VERSION "1.3 corrected-charging-mode-source"

NS_ :

BS_:

BU_: Manager30 BatterySensor RedVisionDisplay TVMS1280 TVMSRogue Bridge

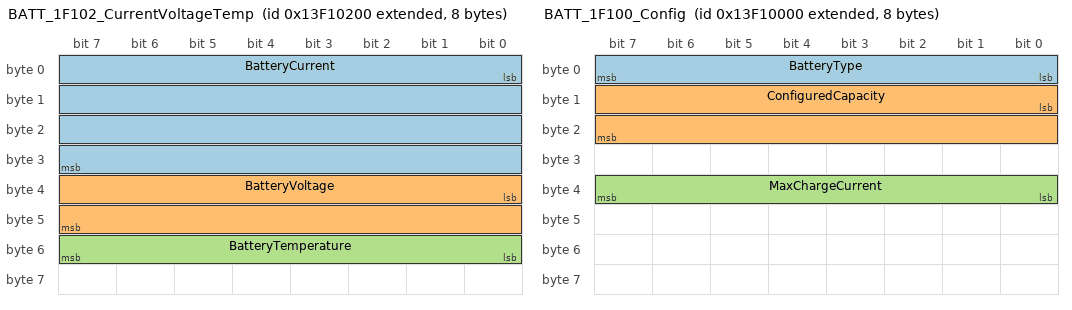
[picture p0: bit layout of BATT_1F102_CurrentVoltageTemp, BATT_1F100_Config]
BO_ 2482045440 BATT_1F102_CurrentVoltageTemp: 8 BatterySensor
 SG_ BatteryCurrent : 0|32@1+ (0.001,-1000) [-1000|1000] "A" Bridge
 SG_ BatteryVoltage : 32|16@1+ (0.001,0) [0|65.535] "V" Bridge
 SG_ BatteryTemperature : 48|8@1+ (1,-60) [-60|195] "degC" Bridge

BO_ 2482045952 BATT_1F104_SOC: 8 BatterySensor
 SG_ BatterySOC : 0|8@1+ (1,0) [0|100] "%" Bridge

BO_ 2482044928 BATT_1F100_Config: 8 BatterySensor
 SG_ BatteryType : 0|8@1+ (1,0) [0|4] "" Bridge
 SG_ ConfiguredCapacity : 8|16@1+ (1,0) [0|65535] "Ah" Bridge
 SG_ MaxChargeCurrent : 32|8@1+ (1,0) [0|254] "A" Bridge

BO_ 2482047488 BATT_1F10A_Alarms: 8 BatterySensor
 SG_ LowSOCAlarm : 8|8@1+ (1,0) [0|100] "%" Bridge
 SG_ LowVoltageAlarm : 16|16@1+ (0.001,0) [0|65.535] "V" Bridge

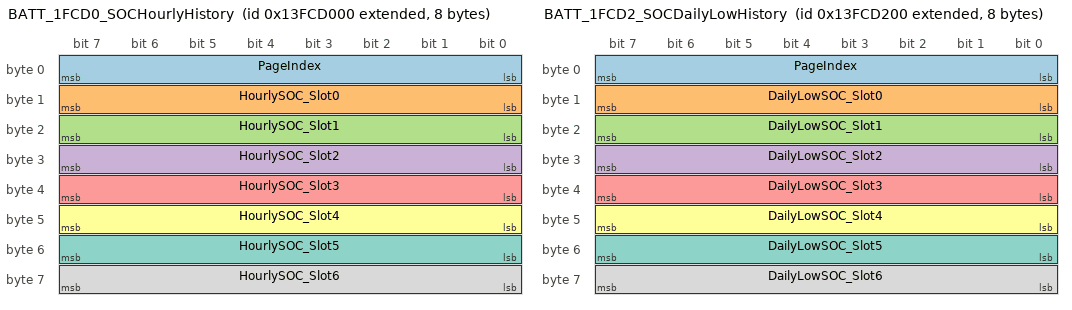
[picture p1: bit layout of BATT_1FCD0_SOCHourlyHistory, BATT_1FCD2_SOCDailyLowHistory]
BO_ 2482819072 BATT_1FCD0_SOCHourlyHistory: 8 BatterySensor
 SG_ PageIndex : 0|8@1+ (1,0) [0|4] "" Bridge
 SG_ HourlySOC_Slot0 : 8|8@1+ (1,0) [0|255] "%" Bridge
 SG_ HourlySOC_Slot1 : 16|8@1+ (1,0) [0|255] "%" Bridge
 SG_ HourlySOC_Slot2 : 24|8@1+ (1,0) [0|255] "%" Bridge
 SG_ HourlySOC_Slot3 : 32|8@1+ (1,0) [0|255] "%" Bridge
 SG_ HourlySOC_Slot4 : 40|8@1+ (1,0) [0|255] "%" Bridge
 SG_ HourlySOC_Slot5 : 48|8@1+ (1,0) [0|255] "%" Bridge
 SG_ HourlySOC_Slot6 : 56|8@1+ (1,0) [0|255] "%" Bridge

BO_ 2482819584 BATT_1FCD2_SOCDailyLowHistory: 8 BatterySensor
 SG_ PageIndex : 0|8@1+ (1,0) [0|4] "" Bridge
 SG_ DailyLowSOC_Slot0 : 8|8@1+ (1,0) [0|255] "%" Bridge
 SG_ DailyLowSOC_Slot1 : 16|8@1+ (1,0) [0|255] "%" Bridge
 SG_ DailyLowSOC_Slot2 : 24|8@1+ (1,0) [0|255] "%" Bridge
 SG_ DailyLowSOC_Slot3 : 32|8@1+ (1,0) [0|255] "%" Bridge
 SG_ DailyLowSOC_Slot4 : 40|8@1+ (1,0) [0|255] "%" Bridge
 SG_ DailyLowSOC_Slot5 : 48|8@1+ (1,0) [0|255] "%" Bridge
 SG_ DailyLowSOC_Slot6 : 56|8@1+ (1,0) [0|255] "%" Bridge

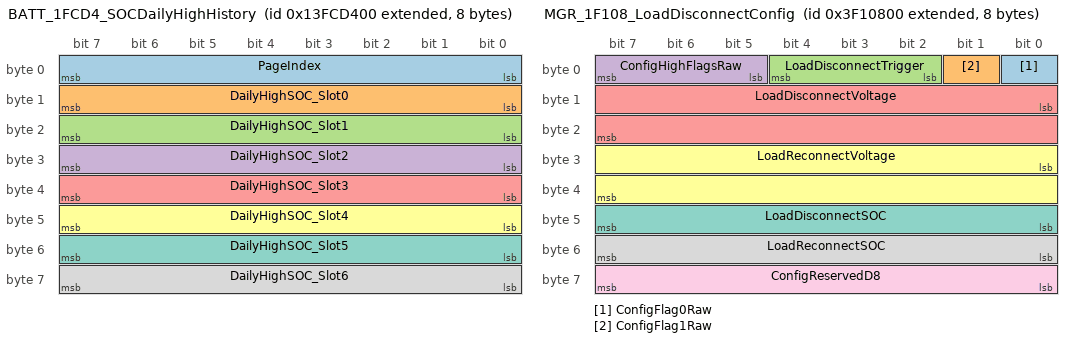
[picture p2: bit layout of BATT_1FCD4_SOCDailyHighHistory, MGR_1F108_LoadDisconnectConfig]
BO_ 2482820096 BATT_1FCD4_SOCDailyHighHistory: 8 BatterySensor
 SG_ PageIndex : 0|8@1+ (1,0) [0|4] "" Bridge
 SG_ DailyHighSOC_Slot0 : 8|8@1+ (1,0) [0|255] "%" Bridge
 SG_ DailyHighSOC_Slot1 : 16|8@1+ (1,0) [0|255] "%" Bridge
 SG_ DailyHighSOC_Slot2 : 24|8@1+ (1,0) [0|255] "%" Bridge
 SG_ DailyHighSOC_Slot3 : 32|8@1+ (1,0) [0|255] "%" Bridge
 SG_ DailyHighSOC_Slot4 : 40|8@1+ (1,0) [0|255] "%" Bridge
 SG_ DailyHighSOC_Slot5 : 48|8@1+ (1,0) [0|255] "%" Bridge
 SG_ DailyHighSOC_Slot6 : 56|8@1+ (1,0) [0|255] "%" Bridge

BO_ 2213677568 MGR_1F20A_OutputCurrentVoltage: 8 Manager30
 SG_ OutputCurrent : 0|32@1+ (0.001,-1000) [-1000|1000] "A" Bridge
 SG_ ManagerBatteryVoltage : 32|16@1+ (0.001,0) [0|65.535] "V" Bridge

BO_ 2213677056 MGR_1F208_Solar: 8 Manager30
 SG_ SolarCurrent : 0|32@1+ (0.001,-1000) [-1000|1000] "A" Bridge
 SG_ SolarVoltage : 32|16@1+ (0.001,0) [0|65.535] "V" Bridge

BO_ 2213676032 MGR_1F204_ACInput: 8 Manager30
 SG_ ACInputCurrent : 0|32@1+ (0.001,-1000) [-1000|1000] "A" Bridge
 SG_ ACInputVoltage : 32|16@1+ (1,0) [0|65535] "V" Bridge

BO_ 2213611520 MGR_1F108_LoadDisconnectConfig: 8 Manager30
 SG_ ConfigFlag0Raw : 0|1@1+ (1,0) [0|1] "" Bridge
 SG_ ConfigFlag1Raw : 1|1@1+ (1,0) [0|1] "" Bridge
 SG_ LoadDisconnectTrigger : 2|3@1+ (1,0) [0|7] "" Bridge
 SG_ ConfigHighFlagsRaw : 5|3@1+ (1,0) [0|7] "" Bridge
 SG_ LoadDisconnectVoltage : 8|16@1+ (0.001,0) [0|65.535] "V" Bridge
 SG_ LoadReconnectVoltage : 24|16@1+ (0.001,0) [0|65.535] "V" Bridge
 SG_ LoadDisconnectSOC : 40|8@1+ (1,0) [0|100] "%" Bridge
 SG_ LoadReconnectSOC : 48|8@1+ (1,0) [0|100] "%" Bridge
 SG_ ConfigReservedD8 : 56|8@1+ (1,0) [0|255] "" Bridge

BO_ 2213675008 MGR_1F200_ChargingStage: 8 Manager30
 SG_ ChargingMode : 0|1@1+ (1,0) [0|1] "" Bridge
 SG_ ChargingStageBase : 1|7@1+ (2,0) [0|254] "" Bridge

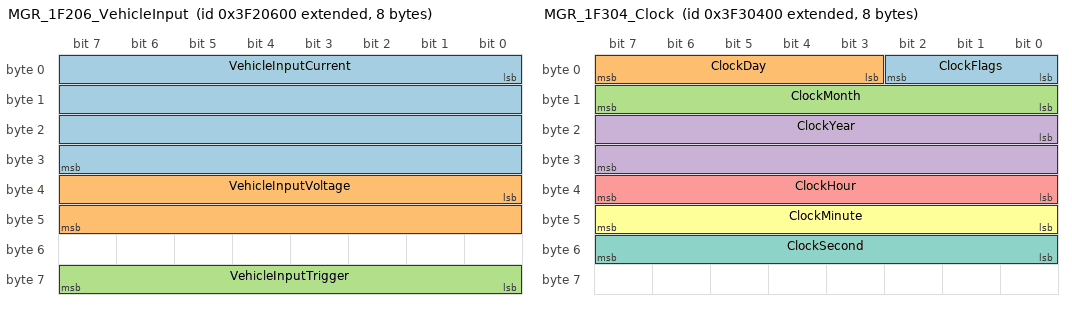
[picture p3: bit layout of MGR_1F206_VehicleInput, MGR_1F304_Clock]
BO_ 2213676544 MGR_1F206_VehicleInput: 8 Manager30
 SG_ VehicleInputCurrent : 0|32@1+ (0.001,-1000) [-1000|1000] "A" Bridge
 SG_ VehicleInputVoltage : 32|16@1+ (0.001,0) [0|65.535] "V" Bridge
 SG_ VehicleInputTrigger : 56|8@1+ (1,0) [0|255] "" Bridge

BO_ 2213741568 MGR_1F304_Clock: 8 Manager30
 SG_ ClockFlags : 0|3@1+ (1,0) [0|7] "" Bridge
 SG_ ClockDay : 3|5@1+ (1,1) [1|31] "" Bridge
 SG_ ClockMonth : 8|8@1+ (1,0) [1|12] "" Bridge
 SG_ ClockYear : 16|16@1+ (1,0) [2000|2100] "" Bridge
 SG_ ClockHour : 32|8@1+ (1,0) [0|23] "" Bridge
 SG_ ClockMinute : 40|8@1+ (1,0) [0|59] "" Bridge
 SG_ ClockSecond : 48|8@1+ (1,0) [0|59] "" Bridge

BO_ 2214385152 MGR_1FCD6_SolarEnergyHistory: 8 Manager30
 SG_ SolarPageIndex M : 0|8@1+ (1,0) [0|3] "" Bridge
 SG_ SolarDay0Wh m0 : 8|16@1+ (1,0) [0|65535] "Wh" Bridge
 SG_ SolarDay1Wh m0 : 24|16@1+ (1,0) [0|65535] "Wh" Bridge
 SG_ SolarDay2Wh m0 : 40|16@1+ (1,0) [0|65535] "Wh" Bridge
 SG_ SolarDay3Wh m1 : 8|16@1+ (1,0) [0|65535] "Wh" Bridge
 SG_ SolarDay4Wh m1 : 24|16@1+ (1,0) [0|65535] "Wh" Bridge
 SG_ SolarDay5Wh m1 : 40|16@1+ (1,0) [0|65535] "Wh" Bridge
 SG_ SolarDay6Wh m2 : 8|16@1+ (1,0) [0|65535] "Wh" Bridge
 SG_ SolarDay7Wh m2 : 24|16@1+ (1,0) [0|65535] "Wh" Bridge
 SG_ SolarDay8Wh m2 : 40|16@1+ (1,0) [0|65535] "Wh" Bridge
 SG_ SolarDay9Wh m3 : 8|16@1+ (1,0) [0|65535] "Wh" Bridge
 SG_ SolarDay10Wh m3 : 24|16@1+ (1,0) [0|65535] "Wh" Bridge
 SG_ SolarDay11Wh m3 : 40|16@1+ (1,0) [0|65535] "Wh" Bridge

BO_ 2482143232 DISP_1F280_DisplayCurrents: 8 RedVisionDisplay
 SG_ BatteryCurrentDisplay : 0|16@1+ (0.1,-1000) [-1000|5553.5] "A" Bridge
 SG_ DeviceCurrentDisplay : 32|16@1+ (0.1,-1000) [-1000|5553.5] "A" Bridge

BO_ 2482143744 DISP_1F282_DisplayMirror: 8 RedVisionDisplay
 SG_ DisplayVehicleCurrent : 16|16@1+ (0.1,-1000) [-1000|5553.5] "A" Bridge
 SG_ ManagerOutputCurrentDisplay : 48|16@1+ (0.1,-1000) [-1000|5553.5] "A" Bridge

BO_ 2482144256 DISP_1F284_DisplayVehicleVoltage: 8 RedVisionDisplay
 SG_ DisplayVehicleVoltage : 16|16@1+ (0.1,0) [0|6553.5] "V" Bridge

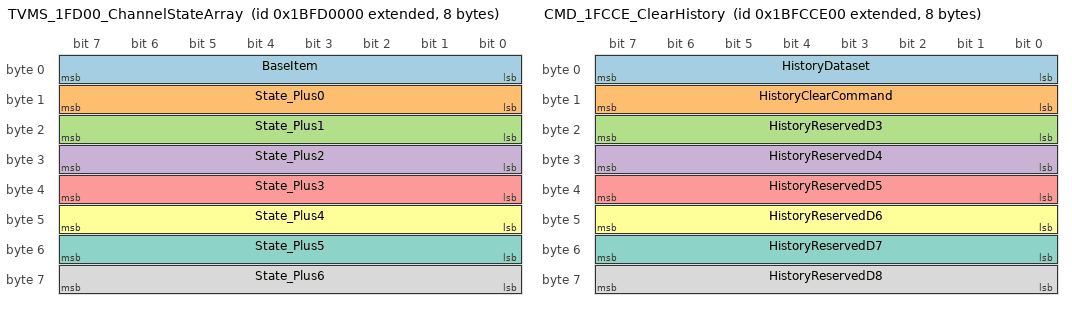
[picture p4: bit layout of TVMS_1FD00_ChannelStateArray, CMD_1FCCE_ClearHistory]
BO_ 2617049088 TVMS_1FD00_ChannelStateArray: 8 Vector__XXX
 SG_ BaseItem : 0|8@1+ (1,0) [0|255] "" Bridge
 SG_ State_Plus0 : 8|8@1+ (1,0) [0|255] "" Bridge
 SG_ State_Plus1 : 16|8@1+ (1,0) [0|255] "" Bridge
 SG_ State_Plus2 : 24|8@1+ (1,0) [0|255] "" Bridge
 SG_ State_Plus3 : 32|8@1+ (1,0) [0|255] "" Bridge
 SG_ State_Plus4 : 40|8@1+ (1,0) [0|255] "" Bridge
 SG_ State_Plus5 : 48|8@1+ (1,0) [0|255] "" Bridge
 SG_ State_Plus6 : 56|8@1+ (1,0) [0|255] "" Bridge

BO_ 2617049600 TVMS_1FD02_MuxSensors: 8 Vector__XXX
 SG_ ItemId M : 0|8@1+ (1,0) [0|255] "" Bridge
 SG_ RogueTank1 m9 : 8|8@1+ (1,0) [0|100] "%" Bridge
 SG_ RogueTank2 m9 : 16|8@1+ (1,0) [0|100] "%" Bridge
 SG_ RogueInputVoltage m22 : 8|16@1+ (0.001,0) [0|65.535] "V" Bridge
 SG_ RogueInputCurrent m22 : 24|16@1+ (0.001,0) [0|65.535] "A" Bridge
 SG_ TVMS1280VoltageInput1 m17 : 8|16@1+ (0.001,0) [0|65.535] "V" Bridge
 SG_ TVMS1280VoltageInput2 m17 : 24|16@1+ (0.001,0) [0|65.535] "V" Bridge
 SG_ TVMS1280Temp2 m17 : 40|8@1+ (1,-100) [-100|155] "degC" Bridge
 SG_ TVMS1280Temp1 m20 : 8|8@1+ (1,-100) [-100|155] "degC" Bridge
 SG_ TVMS1280Tank1 m20 : 24|8@1+ (1,0) [0|100] "%" Bridge
 SG_ TVMS1280Tank2 m20 : 40|8@1+ (1,0) [0|100] "%" Bridge
 SG_ TVMS1280Tank3 m23 : 8|8@1+ (1,0) [0|100] "%" Bridge
 SG_ TVMS1280Tank4 m23 : 24|8@1+ (1,0) [0|100] "%" Bridge
 SG_ TVMS1280Tank5 m23 : 40|8@1+ (1,0) [0|100] "%" Bridge
 SG_ TVMS1280Tank6 m26 : 8|8@1+ (1,0) [0|100] "%" Bridge

BO_ 2617053696 ROGUE_1FD12_OutputLevels: 8 TVMSRogue
 SG_ LevelPageId M : 0|8@1+ (1,0) [0|255] "" Bridge
 SG_ RogueOutput1Level m12 : 8|8@1+ (1,0) [0|100] "%" Bridge
 SG_ RogueOutput2Level m12 : 16|8@1+ (1,0) [0|100] "%" Bridge
 SG_ RogueOutput3Level m12 : 24|8@1+ (1,0) [0|100] "%" Bridge
 SG_ RogueOutput4Level m12 : 32|8@1+ (1,0) [0|100] "%" Bridge
 SG_ RogueOutput5Level m12 : 40|8@1+ (1,0) [0|100] "%" Bridge
 SG_ RogueOutput6Level m12 : 48|8@1+ (1,0) [0|100] "%" Bridge
 SG_ RogueOutput7Level m12 : 56|8@1+ (1,0) [0|100] "%" Bridge
 SG_ RogueOutput8Level m19 : 8|8@1+ (1,0) [0|100] "%" Bridge
 SG_ RogueOutput9Level m19 : 16|8@1+ (1,0) [0|100] "%" Bridge
 SG_ RogueOutput10Level m19 : 24|8@1+ (1,0) [0|100] "%" Bridge

BO_ 2617044992 TVMS1280_1FCF0_InverterStatus: 8 TVMS1280
 SG_ InverterState : 0|8@1+ (1,0) [0|1] "" Bridge
 SG_ InverterItemId : 8|8@1+ (1,0) [0|255] "" Bridge

BO_ 2617036288 CMD_1FCCE_ClearHistory: 8 Bridge
 SG_ HistoryDataset : 0|8@1+ (1,0) [0|255] "" Manager30,BatterySensor
 SG_ HistoryClearCommand : 8|8@1+ (1,0) [252|252] "" Manager30,BatterySensor
 SG_ HistoryReservedD3 : 16|8@1+ (1,0) [255|255] "" Manager30,BatterySensor
 SG_ HistoryReservedD4 : 24|8@1+ (1,0) [255|255] "" Manager30,BatterySensor
 SG_ HistoryReservedD5 : 32|8@1+ (1,0) [255|255] "" Manager30,BatterySensor
 SG_ HistoryReservedD6 : 40|8@1+ (1,0) [255|255] "" Manager30,BatterySensor
 SG_ HistoryReservedD7 : 48|8@1+ (1,0) [255|255] "" Manager30,BatterySensor
 SG_ HistoryReservedD8 : 56|8@1+ (1,0) [255|255] "" Manager30,BatterySensor

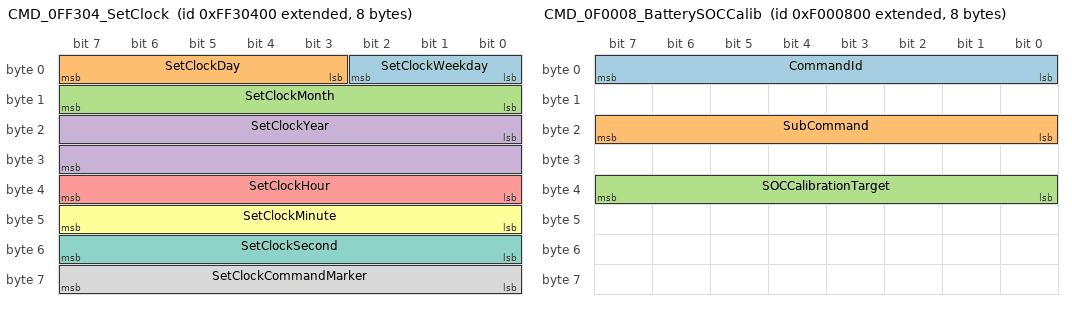
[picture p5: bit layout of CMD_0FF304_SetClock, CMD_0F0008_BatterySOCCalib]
BO_ 2415068160 CMD_0FF304_SetClock: 8 Bridge
 SG_ SetClockWeekday : 0|3@1+ (1,0) [0|7] "" Manager30
 SG_ SetClockDay : 3|5@1+ (1,1) [1|31] "" Manager30
 SG_ SetClockMonth : 8|8@1+ (1,0) [1|12] "" Manager30
 SG_ SetClockYear : 16|16@1+ (1,0) [2000|2100] "" Manager30
 SG_ SetClockHour : 32|8@1+ (1,0) [0|23] "" Manager30
 SG_ SetClockMinute : 40|8@1+ (1,0) [0|59] "" Manager30
 SG_ SetClockSecond : 48|8@1+ (1,0) [0|59] "" Manager30
 SG_ SetClockCommandMarker : 56|8@1+ (1,0) [0|0] "" Manager30

BO_ 2399207168 CMD_0F00FF_ConfigSetting: 8 Bridge
 SG_ CommandId : 0|8@1+ (1,0) [0|255] "" Manager30,BatterySensor
 SG_ ConfigValue : 32|16@1+ (1,0) [0|65535] "" Manager30,BatterySensor

BO_ 2399143936 CMD_0F0008_BatterySOCCalib: 8 Bridge
 SG_ CommandId : 0|8@1+ (1,0) [0|255] "" BatterySensor
 SG_ SubCommand : 16|8@1+ (1,0) [0|255] "" BatterySensor
 SG_ SOCCalibrationTarget : 32|8@1+ (1,0) [0|100] "%" BatterySensor

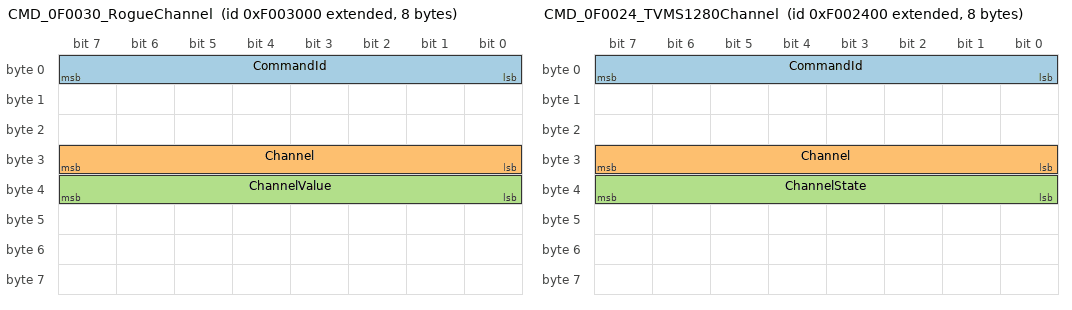
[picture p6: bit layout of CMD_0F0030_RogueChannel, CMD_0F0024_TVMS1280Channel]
BO_ 2399154176 CMD_0F0030_RogueChannel: 8 Bridge
 SG_ CommandId : 0|8@1+ (1,0) [0|255] "" TVMSRogue
 SG_ Channel : 24|8@1+ (1,0) [0|255] "" TVMSRogue
 SG_ ChannelValue : 32|8@1+ (1,0) [0|100] "" TVMSRogue

BO_ 2399151104 CMD_0F0024_TVMS1280Channel: 8 Bridge
 SG_ CommandId : 0|8@1+ (1,0) [0|255] "" TVMS1280
 SG_ Channel : 24|8@1+ (1,0) [0|255] "" TVMS1280
 SG_ ChannelState : 32|8@1+ (1,0) [0|1] "" TVMS1280

BO_ 2415710208 REQ_0FFCD0_SOCHourlyPoll: 8 Bridge

BO_ 2415710720 REQ_0FFCD2_SOCDailyLowPoll: 8 Bridge

BO_ 2415711232 REQ_0FFCD4_SOCDailyHighPoll: 8 Bridge

BO_ 2415711744 REQ_0FFCD6_SolarHistoryPoll: 8 Bridge

CM_ "RedVision / TVMS CAN bridge - signals reflect ONLY what the ESPHome components decode and transmit.";
CM_ BU_ Bridge "This ESP32 / ESPHome CAN bridge. Source address is configurable (host_address, default 0x22).";
CM_ BO_ 2482045440 "29-bit extended IDs. Receivers key on DGN=(ID>>8)&0x1FFFF and source address=ID&0xFF. Message IDs here have the source-address byte (low 8 bits) set to 0x00 so one definition matches a DGN from ANY source address; OR the real source byte in when transmitting/filtering. Observed source addresses: Manager30 0x01, BatterySensor 0x08, RedVision displays 0x20/0x21, TVMS1280 0x24, TVMSRogue 0x30, Bridge 0x22.";
CM_ BO_ 2482819072 "Paginated history array. PageIndex (D1) selects the block; absolute hour index = PageIndex*7 + SlotN. Value 255 (0xFF) means no data.";
CM_ BO_ 2482819584 "Paginated history array. Absolute day index = PageIndex*7 + SlotN. 255 = no data. Combined with the daily-high page into the SOC Daily Range entity.";
CM_ BO_ 2482820096 "Paginated history array. Absolute day index = PageIndex*7 + SlotN. 255 = no data.";
CM_ BO_ 2213611520 "Manager30 DGN 0x1F108 is load-disconnect configuration, not charging mode. In the storage-mode transition capture D1 remained 0xEC (bit 0 clear) while command 0x43 set Storage and 0x1F200 changed to 0x21. D1 bits2-4 are the load-disconnect trigger; D2-D3 disconnect voltage, D4-D5 reconnect voltage, D6 disconnect SOC and D7 reconnect SOC.";
CM_ BO_ 2213675008 "Manager30 charging stage on D1. ChargingStageBase is bits 1-7 with factor 2, so its displayed physical value equals D1 & 0xFE. D1 bit0 is a Touring/Storage startup hint (0=Touring, 1=Storage); retained mode is authoritative from command 0x43. Confirmed stages: 0x00 Not Charging, 0x10 Desulphation, 0x20 Soft Start, 0x30 Boost, 0x40 Absorption, 0x50 Battery Test, 0x60 Equalize, 0x70 Float, 0x80 Maintenance.";
CM_ BO_ 2213741568 "Manager30 clock/status response. D1 bits 7-3 encode day-1; D1 bits 2-0 encode weekday (1=Monday through 7=Sunday). D2=month, D3-D4=year little-endian, D5=hour, D6=minute, D7=second, D8 is normally 0xFF. Observed from source address 0x01.";
CM_ BO_ 2214385152 "Solar generation history, 4 pages x 3 days = 12 days. Day 0 = today, Day 1..11 = previous days, in Wh. Requested via REQ_0FFCD6 (RTR).";
CM_ BO_ 2617049088 "DGN 0x1FD00 shared by TVMS1280 (SA 0x24) and TVMSRogue (SA 0x30). Byte array: BaseItem (D1) then State_Plus0..6 for channels BaseItem..BaseItem+6. Status codes: 0x00 Off, 0x01 On, 0x06 Fuse blown, 0x0A Output over temp, 0x14 Off override, 0x15 On override, 0xF8 Unconfigured, 0xFF no-data. TVMS1280 channel map: 0x01-0x03 Digital Inputs 1-3, 0x04-0x0D Outputs 1-10, 0x0E Inverter, 0x0F Master. TVMSRogue channel map: 0x01-0x08 Input Buttons 1-8, 0x0B Master, 0x0C-0x15 Outputs 1-10.";
CM_ BO_ 2617049600 "DGN 0x1FD02 shared by TVMS1280 (SA 0x24) and TVMSRogue (SA 0x30), multiplexed by ItemId (D1). Item codes do not collide between the two devices, so one definition serves both.";
CM_ BO_ 2617053696 "TVMSRogue dimmable-output levels, multiplexed by LevelPageId (D1): page 0x0C carries outputs 1-7, page 0x13 carries outputs 8-10.";
CM_ BO_ 2617044992 "TVMS1280 inverter status. InverterState (D1) is on/off when InverterItemId (D2) == 0x0E.";
CM_ BO_ 2399207168 "Config command from the bridge. ID = 0x0F00FF<host_address>. CommandId (D1) selects the setting; ConfigValue starts at D5. Command 0x43 sets charging mode: 0=Touring, 1=Storage. Targets Manager30 and BatterySensor settings (D3=D4=0xFF).";
CM_ BO_ 2399143936 "Battery SOC full calibration. ID = 0x0F00<battery_SA><host_address>, e.g. 0x0F000822. D1=0x15, D3=0x03, D5=target percent.";
CM_ BO_ 2399154176 "TVMSRogue output command. ID = 0x0F00<rogue_SA><host_address>. CommandId 0xCB = on/off (ChannelValue 0/1), 0x5A = absolute level (ChannelValue 0-100%). Channel 0x0B Master, 0x0C-0x15 Outputs 1-10.";
CM_ BO_ 2399151104 "TVMS1280 output command. ID = 0x0F00<1280_SA><host_address>. CommandId 0xCB, Channel 0x04-0x0D Outputs 1-10, 0x0E Inverter, 0x0F Master, ChannelState 0/1.";
CM_ BO_ 2415710208 "RTR remote-request frame (no payload, DLC 8). Polls the battery for SOC hourly history; reply is BATT_1FCD0.";
CM_ BO_ 2415710720 "RTR remote-request frame (no payload). Polls SOC daily-low history; reply is BATT_1FCD2.";
CM_ BO_ 2415711232 "RTR remote-request frame (no payload). Polls SOC daily-high history; reply is BATT_1FCD4.";
CM_ BO_ 2415711744 "RTR remote-request frame (no payload). Polls the manager for solar history; reply is MGR_1FCD6.";
CM_ BO_ 2415068160 "CONFIRMED Manager30 set-clock command. Actual CAN ID is 0x0FF304<source_address>; this DBC leaves the source byte at 0x00, so OR in the transmitting host address. D1=((day-1)<<3)|weekday, where weekday 1=Monday through 7=Sunday. D2=month, D3-D4=year little-endian, D5=hour, D6=minute, D7=second, D8=0x00. Confirmed example: ID 0x0FF304FA, B2 06 EA 07 10 23 29 00 set 23 June 2026 16:35:41 Tuesday. Manager30 confirmed approximately 230 ms later on 0x03F30401.";
CM_ BO_ 2617036288 "CONFIRMED history-clear command. Actual CAN ID is 0x1BFCCE<source_address>; this compact DBC leaves the source byte at 0x00. D1 selects the history dataset, D2 must be 0xFC, and D3-D8 must be 0xFF. Confirmed selectors: 0xD0=Hourly SOC history (reply DGN 0x1FCD0), 0xD2=Daily Low SOC history (reply 0x1FCD2), 0xD4=Daily High SOC history (reply 0x1FCD4), and 0xD6=Solar Energy history (reply 0x1FCD6). Observed from RedVision source 0x20 as CAN ID 0x1BFCCE20. No separate acknowledgement was identified; deletion was confirmed by reading back zeroed history pages.";
CM_ SG_ 2617036288 HistoryDataset "History dataset selector: D0=Hourly SOC, D2=Daily Low SOC, D4=Daily High SOC, D6=Solar Energy.";
CM_ SG_ 2617036288 HistoryClearCommand "Clear/delete command marker. Confirmed value is 0xFC.";
CM_ SG_ 2617036288 HistoryReservedD3 "Required constant 0xFF in confirmed clear-history commands.";
CM_ SG_ 2617036288 HistoryReservedD4 "Required constant 0xFF in confirmed clear-history commands.";
CM_ SG_ 2617036288 HistoryReservedD5 "Required constant 0xFF in confirmed clear-history commands.";
CM_ SG_ 2617036288 HistoryReservedD6 "Required constant 0xFF in confirmed clear-history commands.";
CM_ SG_ 2617036288 HistoryReservedD7 "Required constant 0xFF in confirmed clear-history commands.";
CM_ SG_ 2617036288 HistoryReservedD8 "Required constant 0xFF in confirmed clear-history commands.";
CM_ SG_ 2482045440 BatteryCurrent "Signed via offset: A = raw/1000 - 1000. Positive = charging, negative = discharging.";
CM_ SG_ 2213677568 OutputCurrent "A = raw/1000 - 1000.";
CM_ SG_ 2482143232 BatteryCurrentDisplay "Display rebroadcast value: A = raw/10 - 1000.";
CM_ BO_ 2213676032 "Native Manager30 AC input. ACInputCurrent D1-D4 (raw/1000 - 1000 A, 0.001 A resolution), ACInputVoltage D5-D6 (1 V/count). Example 0x03F20401 E8 42 0F 00 EF 00 FD FF -> 0.168 A, 239 V. Preferred over the display rebroadcast 0x1F282 which is rounded to 0.1 A.";
CM_ SG_ 2213676032 ACInputCurrent "A = raw/1000 - 1000.";
CM_ BO_ 2213676544 "Native Manager30 vehicle input, ~10 Hz. Confirmed from capture (224 frames): current D1-D4, voltage D5-D6, mode trigger D8. Example 0x03F20601 40 42 0F 00 31 31 FC 01 -> 0.000 A, 12.593 V, trigger 0x01.";
CM_ SG_ 2213676544 VehicleInputCurrent "Confirmed: A = raw/1000 - 1000. Constant 0 A across the capture.";
CM_ SG_ 2213676544 VehicleInputVoltage "Confirmed: V = raw/1000. Ranged 12.552-12.629 V across the capture.";
CM_ BO_ 2482143744 "RedVision display mirror, ~1 Hz. DisplayVehicleCurrent (D3-D4) and ManagerOutputCurrentDisplay (D7-D8) both scale 0.1, offset -1000.";
CM_ BO_ 2482144256 "RedVision display mirror of the Manager30 vehicle input voltage, ~1 Hz. D3-D4, scale 0.1 V. Example 0x13F28420 F1 00 7D 00 ... -> 12.5 V.";
CM_ SG_ 2617049600 RogueInputCurrent "CONFIRMED: DGN 0x1FD02, page 0x16, D4-D5 little-endian. Rogue input current in amperes = raw * 0.001. Controlled capture rose from approximately 0.05 A to 8.781 A and returned to approximately 0.05 A.";
CM_ SG_ 2213611520 ConfigFlag0Raw "D1 bit0 is a raw load-disconnect configuration flag. It is not charging mode.";
CM_ SG_ 2213675008 ChargingMode "D1 bit0. 0=Touring mode, 1=Storage mode. Use as a startup hint; command 0x43 is retained and authoritative once observed.";
CM_ SG_ 2213675008 ChargingStageBase "Bits 1-7 of D1 with factor 2. The physical value equals D1 & 0xFE and should be interpreted using the charging-stage enum.";

VAL_ 2617036288 HistoryDataset 208 "HourlySOCHistory" 210 "DailyLowSOCHistory" 212 "DailyHighSOCHistory" 214 "SolarEnergyHistory" ;
VAL_ 2617036288 HistoryClearCommand 252 "ClearDelete" ;

VAL_ 2415068160 SetClockWeekday 0 "Unknown" 1 "Monday" 2 "Tuesday" 3 "Wednesday" 4 "Thursday" 5 "Friday" 6 "Saturday" 7 "Sunday" ;
VAL_ 2213741568 ClockFlags 0 "Unknown" 1 "Monday" 2 "Tuesday" 3 "Wednesday" 4 "Thursday" 5 "Friday" 6 "Saturday" 7 "Sunday" ;

VAL_ 2482044928 BatteryType 0 "Gel" 1 "AGM" 2 "LeadAcid" 3 "Calcium" 4 "Lithium" ;
VAL_ 2213611520 LoadDisconnectTrigger 0 "Always" 1 "BMSVoltage" 2 "BMSSOC" 3 "Never" 4 "Voltage" ;
VAL_ 2213675008 ChargingMode 0 "Touring" 1 "Storage" ;
VAL_ 2213675008 ChargingStageBase 0 "NotCharging" 8 "Desulphation" 16 "SoftStart" 24 "Boost" 32 "Absorption" 40 "BatteryTest" 48 "Equalize" 56 "Float" 64 "Maintenance" ;
VAL_ 2213676544 VehicleInputTrigger 0 "Auto" 1 "12V" 2 "24V" 3 "Ignition" 5 "On" ;
VAL_ 2399207168 CommandId 17 "SetBatteryType" 18 "SetConfiguredCapacity" 20 "SetMaxChargeCurrent" 65 "SetLowSOCAlarm" 66 "SetLowVoltageAlarm" 67 "SetChargingMode" 104 "SetVehicleInputTrigger" ;
VAL_ 2399154176 CommandId 203 "SetOnOff" 90 "SetLevel" ;
VAL_ 2399151104 CommandId 203 "SetOnOff" ;
VAL_ 2617049088 State_Plus0 0 "Off" 1 "On" 6 "FuseBlown" 10 "OutputOverTemp" 20 "OffOverride" 21 "OnOverride" 248 "Unconfigured" ;
VAL_ 2617049088 State_Plus1 0 "Off" 1 "On" 6 "FuseBlown" 10 "OutputOverTemp" 20 "OffOverride" 21 "OnOverride" 248 "Unconfigured" ;
VAL_ 2617049088 State_Plus2 0 "Off" 1 "On" 6 "FuseBlown" 10 "OutputOverTemp" 20 "OffOverride" 21 "OnOverride" 248 "Unconfigured" ;
VAL_ 2617049088 State_Plus3 0 "Off" 1 "On" 6 "FuseBlown" 10 "OutputOverTemp" 20 "OffOverride" 21 "OnOverride" 248 "Unconfigured" ;
VAL_ 2617049088 State_Plus4 0 "Off" 1 "On" 6 "FuseBlown" 10 "OutputOverTemp" 20 "OffOverride" 21 "OnOverride" 248 "Unconfigured" ;
VAL_ 2617049088 State_Plus5 0 "Off" 1 "On" 6 "FuseBlown" 10 "OutputOverTemp" 20 "OffOverride" 21 "OnOverride" 248 "Unconfigured" ;
VAL_ 2617049088 State_Plus6 0 "Off" 1 "On" 6 "FuseBlown" 10 "OutputOverTemp" 20 "OffOverride" 21 "OnOverride" 248 "Unconfigured" ;
